VERSION "BYD Tang DM 2018 - sunnypilot 0.10.1"

NS_ :

BS_:

BU_: VCU EPS ESP MPC BCM RADAR

CM_ "BYD Tang DM 2018 CAN Database for sunnypilot";
CM_ "Version: 2026.02";
CM_ "Optimized for 18款比亚迪唐DM";

BO_ 85 EPB: 8 ESP
 SG_ EPB_ActiveFlag : 40|1@1+ (1,0) [0|1] "" VCU
 SG_ CheckSum : 56|8@1+ (1,0) [0|255] "" VCU

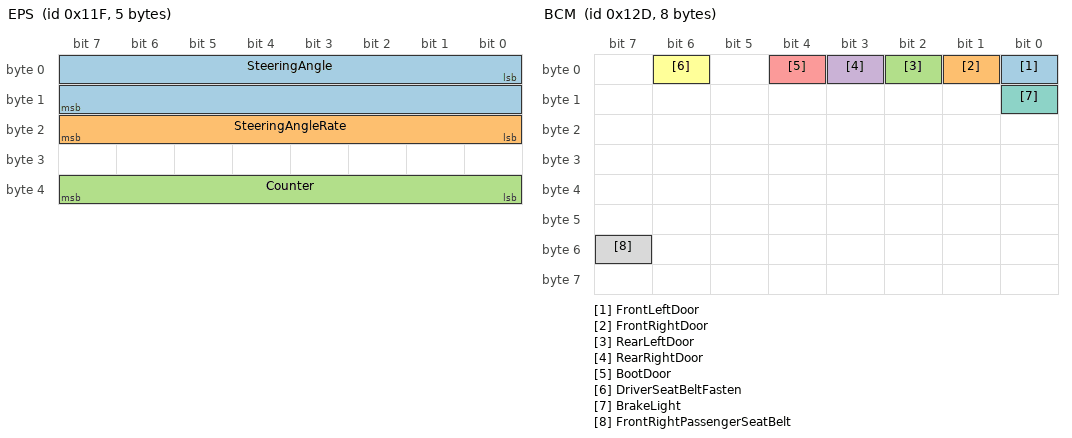
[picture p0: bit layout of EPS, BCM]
BO_ 287 EPS: 5 EPS
 SG_ SteeringAngle : 0|16@1- (0.1,0) [-450|450] "deg" VCU,MPC
 SG_ SteeringAngleRate : 16|8@1+ (4,0) [0|1020] "deg/s" VCU,MPC
 SG_ Counter : 32|8@1+ (1,0) [0|255] "" VCU

BO_ 289 CARSPEED: 8 VCU
 SG_ CarDisplaySpeed : 0|12@1+ (1,0) [0|255] "km/h" EPS,MPC

BO_ 301 BCM: 8 BCM
 SG_ FrontLeftDoor : 0|1@0+ (1,0) [0|1] "" VCU
 SG_ FrontRightDoor : 1|1@0+ (1,0) [0|1] "" VCU
 SG_ RearLeftDoor : 2|1@0+ (1,0) [0|1] "" VCU
 SG_ RearRightDoor : 3|1@0+ (1,0) [0|1] "" VCU
 SG_ BootDoor : 4|1@0+ (1,0) [0|1] "" VCU
 SG_ DriverSeatBeltFasten : 6|1@0+ (1,0) [0|1] "" VCU
 SG_ BrakeLight : 8|1@0+ (1,0) [0|1] "" VCU
 SG_ FrontRightPassengerSeatBelt : 55|1@0+ (1,0) [0|1] "" VCU

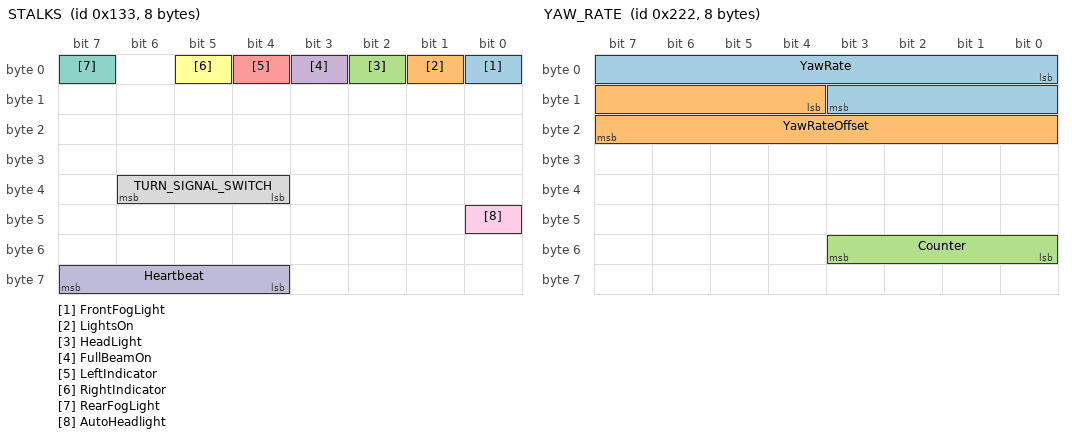
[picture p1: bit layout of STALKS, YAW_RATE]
BO_ 307 STALKS: 8 BCM
 SG_ FrontFogLight : 0|1@0+ (1,0) [0|1] "" VCU
 SG_ LightsOn : 1|1@1+ (1,0) [0|1] "" VCU
 SG_ HeadLight : 2|1@1+ (1,0) [0|1] "" VCU
 SG_ FullBeamOn : 3|1@1+ (1,0) [0|1] "" VCU
 SG_ LeftIndicator : 4|1@0+ (1,0) [0|1] "" VCU,MPC
 SG_ RightIndicator : 5|1@0+ (1,0) [0|1] "" VCU,MPC
 SG_ RearFogLight : 7|1@0+ (1,0) [0|1] "" VCU
 SG_ TURN_SIGNAL_SWITCH : 36|3@1+ (1,0) [0|7] "" VCU
 SG_ AutoHeadlight : 40|1@0+ (1,0) [0|1] "" VCU
 SG_ Heartbeat : 63|4@0+ (1,0) [0|15] "" VCU

BO_ 546 YAW_RATE: 8 ESP
 SG_ YawRate : 0|12@1+ (0.002133,-2.094) [-2.0|2.0] "rad/s" VCU,MPC
 SG_ YawRateOffset : 12|12@1+ (0.002133,-0.13) [-0.1|0.1] "rad/s" VCU
 SG_ Counter : 48|4@1+ (1,0) [0|15] "" VCU

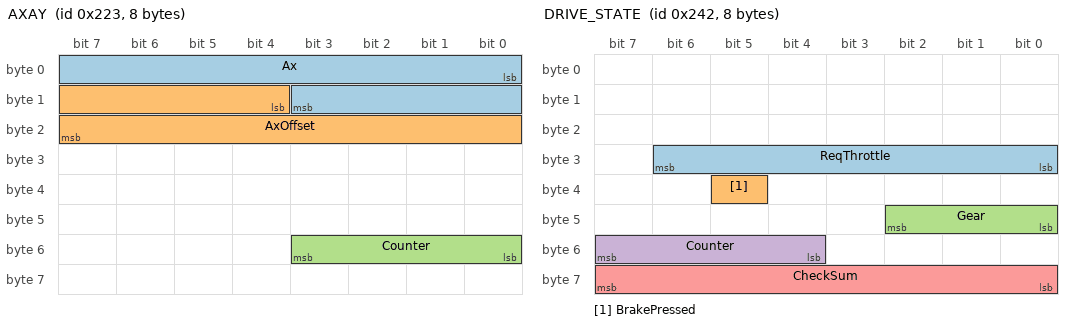
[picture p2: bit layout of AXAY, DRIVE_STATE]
BO_ 547 AXAY: 8 ESP
 SG_ Ax : 0|12@1+ (0.027167,-21.593) [-10.0|10.0] "m/s^2" VCU,MPC
 SG_ AxOffset : 12|12@1+ (0.027127,-21.593) [-1.0|1.0] "m/s^2" VCU
 SG_ Counter : 48|4@1+ (1,0) [0|15] "" VCU

BO_ 578 DRIVE_STATE: 8 VCU
 SG_ ReqThrottle : 30|7@0+ (1,0) [0|127] "%" EPS
 SG_ BrakePressed : 37|1@0+ (1,0) [0|1] "" EPS,MPC
 SG_ Gear : 40|3@1+ (1,0) [0|7] "" EPS,MPC
 SG_ Counter : 55|4@0+ (1,0) [0|15] "" EPS
 SG_ CheckSum : 56|8@1+ (1,0) [0|255] "" EPS

BO_ 660 BELT: 8 BCM
 SG_ SeatBeat : 16|2@1+ (1,0) [0|3] "" VCU

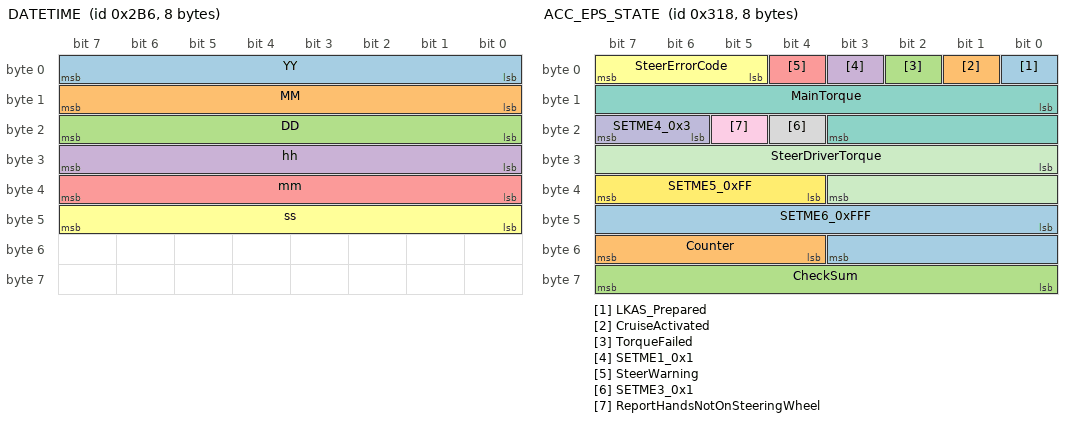
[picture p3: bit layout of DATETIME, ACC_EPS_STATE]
BO_ 694 DATETIME: 8 BCM
 SG_ YY : 7|8@0+ (1,0) [0|255] "" VCU
 SG_ MM : 15|8@0+ (1,0) [0|255] "" VCU
 SG_ DD : 23|8@0+ (1,0) [0|255] "" VCU
 SG_ hh : 31|8@0+ (1,0) [0|255] "" VCU
 SG_ mm : 39|8@0+ (1,0) [0|255] "" VCU
 SG_ ss : 47|8@0+ (1,0) [0|255] "" VCU

BO_ 790 ACC_MPC_STATE: 8 MPC
 SG_ AutoFullBeamState : 3|4@0+ (1,0) [0|15] "" VCU
 SG_ LeftLaneState : 4|2@1+ (1,0) [0|3] "" VCU
 SG_ LKAS_Config : 6|2@1+ (1,0) [0|3] "" VCU
 SG_ SETME2_0x1 : 8|2@1+ (1,0) [0|3] "" VCU
 SG_ ReqHandsOnSteeringWheel : 10|1@1+ (1,0) [0|1] "" VCU
 SG_ MPC_State : 11|4@1+ (1,0) [0|15] "" VCU
 SG_ AutoFullBeam_OnOff : 15|1@0+ (1,0) [0|1] "" VCU
 SG_ LKAS_Output : 16|11@1- (1,0) [-1024|1023] "" EPS
 SG_ LKAS_ReqPrepare : 27|1@1+ (1,0) [0|1] "" EPS
 SG_ LKAS_Active : 28|1@1+ (1,0) [0|1] "" EPS,VCU
 SG_ SETME3_0x0 : 29|1@0+ (1,0) [0|1] "" VCU
 SG_ TrafficSignRecognition_OnOff : 30|1@0+ (1,0) [0|1] "" VCU
 SG_ SETME4_0x0 : 31|1@0+ (1,0) [0|1] "" VCU
 SG_ SETME5_0x1 : 32|2@1+ (1,0) [0|3] "" VCU
 SG_ RightLaneState : 34|2@1+ (1,0) [0|3] "" VCU
 SG_ LKAS_State : 36|4@1+ (1,0) [0|15] "" VCU
 SG_ TrafficSignRecognition_Result : 40|8@1+ (5,-5) [-5|1270] "km/h" VCU
 SG_ LKAS_AlarmType : 49|2@0+ (1,0) [0|3] "" VCU
 SG_ SETME7_0x3 : 51|2@0+ (1,0) [0|3] "" VCU
 SG_ Counter : 52|4@1+ (1,0) [0|15] "" VCU
 SG_ CheckSum : 56|8@1+ (1,0) [0|255] "" VCU

BO_ 792 ACC_EPS_STATE: 8 EPS
 SG_ LKAS_Prepared : 0|1@1+ (1,0) [0|1] "" MPC
 SG_ CruiseActivated : 1|1@1+ (1,0) [0|1] "" MPC
 SG_ TorqueFailed : 2|1@1+ (1,0) [0|1] "" MPC
 SG_ SETME1_0x1 : 3|1@1+ (1,0) [0|1] "" MPC
 SG_ SteerWarning : 4|1@1+ (1,0) [0|1] "" MPC,VCU
 SG_ SteerErrorCode : 5|3@1+ (1,0) [0|7] "" MPC,VCU
 SG_ MainTorque : 8|12@1- (1,0) [-2048|2047] "" MPC
 SG_ SETME3_0x1 : 20|1@1+ (1,0) [0|1] "" MPC
 SG_ ReportHandsNotOnSteeringWheel : 21|1@1+ (1,0) [0|1] "" MPC,VCU
 SG_ SETME4_0x3 : 22|2@1+ (1,0) [0|3] "" MPC
 SG_ SteerDriverTorque : 24|12@1- (1,0) [-2048|2047] "" MPC,VCU
 SG_ SETME5_0xFF : 36|4@1+ (1,0) [0|15] "" MPC
 SG_ SETME6_0xFFF : 40|12@1+ (1,0) [0|4095] "" MPC
 SG_ Counter : 52|4@1+ (1,0) [0|15] "" MPC
 SG_ CheckSum : 56|8@1+ (1,0) [0|255] "" MPC

BO_ 813 ACC_HUD_ADAS: 8 MPC
 SG_ SetSpeed : 0|9@1+ (0.5,0) [0|255.5] "km/h" VCU
 SG_ HasLead : 9|1@1+ (1,0) [0|1] "" VCU
 SG_ SetDistance : 10|3@1+ (1,0) [0|7] "" VCU
 SG_ LeadingDistance : 13|3@1+ (1,0) [0|7] "" VCU
 SG_ AEB : 16|1@1+ (1,0) [0|1] "" VCU,ESP
 SG_ FCW : 17|1@1+ (1,0) [0|1] "" VCU
 SG_ SETME1_0x1 : 18|1@1+ (1,0) [0|1] "" VCU
 SG_ AccState : 19|3@1+ (1,0) [0|7] "" VCU
 SG_ AccOn1 : 22|1@0+ (1,0) [0|1] "" VCU
 SG_ CloseWarning : 23|1@0+ (1,0) [0|1] "" VCU
 SG_ SETME2_0x1 : 24|1@1+ (1,0) [0|1] "" VCU
 SG_ Notify : 25|7@1+ (1,0) [0|127] "" VCU
 SG_ Status : 32|4@1+ (1,0) [0|15] "" VCU
 SG_ SETME3_0xFFF : 36|12@1+ (1,0) [0|4095] "" VCU
 SG_ Counter : 48|4@1+ (1,0) [0|15] "" VCU
 SG_ SETME4_0xF : 55|4@0+ (1,0) [0|15] "" VCU
 SG_ CheckSum : 56|8@1+ (1,0) [0|255] "" VCU

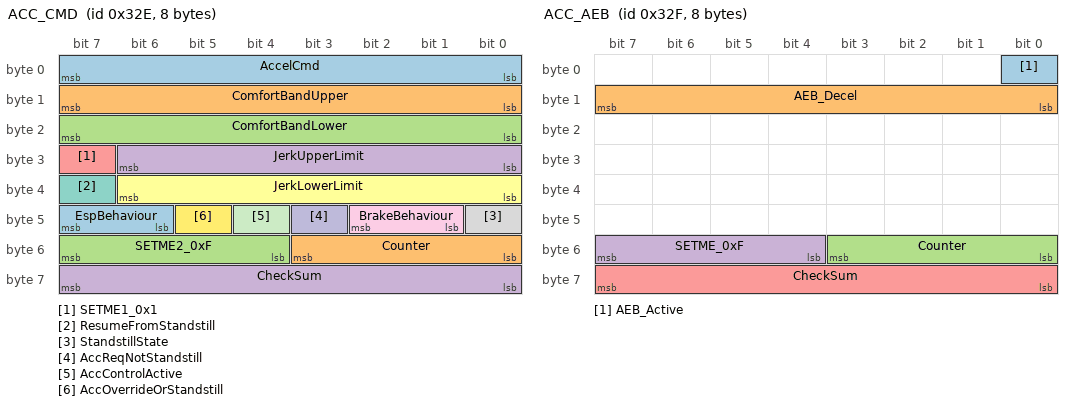
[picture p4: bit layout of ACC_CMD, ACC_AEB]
BO_ 814 ACC_CMD: 8 MPC
 SG_ AccelCmd : 0|8@1+ (0.05,-5) [-5|7.75] "m/s^2" ESP
 SG_ ComfortBandUpper : 8|8@1+ (0.05,-5) [-5|7.75] "m/s^2" ESP
 SG_ ComfortBandLower : 16|8@1+ (0.05,-5) [-5|7.75] "m/s^2" ESP
 SG_ JerkUpperLimit : 24|7@1+ (0.2,0) [0|12.7] "m/s^3" ESP
 SG_ SETME1_0x1 : 31|1@0+ (1,0) [0|1] "" ESP
 SG_ JerkLowerLimit : 32|7@1+ (0.2,-16) [-16|12.7] "m/s^3" ESP
 SG_ ResumeFromStandstill : 39|1@0+ (1,0) [0|1] "" ESP
 SG_ StandstillState : 40|1@0+ (1,0) [0|1] "" ESP
 SG_ BrakeBehaviour : 41|2@1+ (1,0) [0|3] "" ESP
 SG_ AccReqNotStandstill : 43|1@1+ (1,0) [0|1] "" ESP
 SG_ AccControlActive : 44|1@0+ (1,0) [0|1] "" ESP
 SG_ AccOverrideOrStandstill : 45|1@0+ (1,0) [0|1] "" ESP
 SG_ EspBehaviour : 46|2@1+ (1,0) [0|3] "" ESP
 SG_ Counter : 48|4@1+ (1,0) [0|15] "" ESP
 SG_ SETME2_0xF : 55|4@0+ (1,0) [0|15] "" ESP
 SG_ CheckSum : 56|8@1+ (1,0) [0|255] "" ESP

BO_ 815 ACC_AEB: 8 MPC
 SG_ AEB_Active : 0|1@1+ (1,0) [0|1] "" ESP
 SG_ AEB_Decel : 8|8@1+ (0.05,0) [0|12.75] "m/s^2" ESP
 SG_ Counter : 48|4@1+ (1,0) [0|15] "" ESP
 SG_ SETME_0xF : 55|4@0+ (1,0) [0|15] "" ESP
 SG_ CheckSum : 56|8@1+ (1,0) [0|255] "" ESP

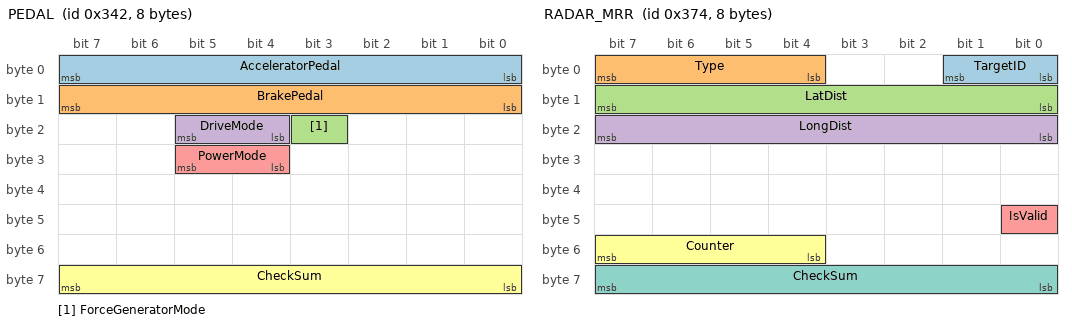
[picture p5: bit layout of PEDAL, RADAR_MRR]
BO_ 834 PEDAL: 8 VCU
 SG_ AcceleratorPedal : 0|8@1+ (0.01,0) [0|2.55] "" MPC
 SG_ BrakePedal : 8|8@1+ (0.01,0) [0|2.55] "" MPC
 SG_ ForceGeneratorMode : 19|1@1+ (1,0) [0|1] "" MPC
 SG_ DriveMode : 20|2@1+ (1,0) [0|3] "" MPC
 SG_ PowerMode : 28|2@1+ (1,0) [0|3] "" MPC
 SG_ CheckSum : 56|8@1+ (1,0) [0|255] "" MPC

BO_ 884 RADAR_MRR: 8 RADAR
 SG_ TargetID : 1|2@0+ (1,0) [0|3] "" MPC
 SG_ Type : 7|4@0+ (1,0) [0|15] "" MPC
 SG_ LatDist : 15|8@0+ (0.1,-12) [-12|13.5] "m" MPC
 SG_ LongDist : 23|8@0+ (1,-100) [-100|155] "m" MPC
 SG_ IsValid : 40|1@0+ (1,0) [0|1] "" MPC
 SG_ Counter : 52|4@1+ (1,0) [0|15] "" MPC
 SG_ CheckSum : 56|8@1+ (1,0) [0|255] "" MPC

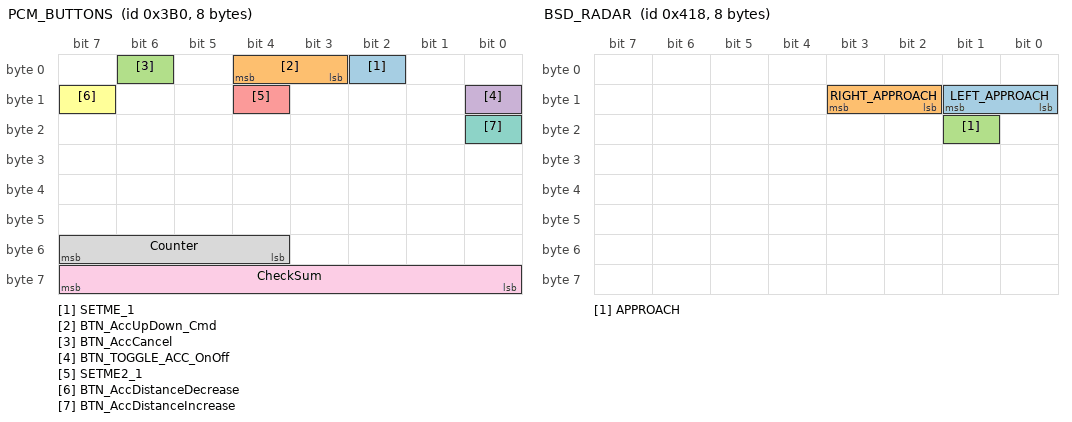
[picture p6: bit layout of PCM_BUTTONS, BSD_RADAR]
BO_ 944 PCM_BUTTONS: 8 BCM
 SG_ SETME_1 : 2|1@0+ (1,0) [0|1] "" VCU
 SG_ BTN_AccUpDown_Cmd : 4|2@0+ (1,0) [0|3] "" VCU,MPC
 SG_ BTN_AccCancel : 6|1@0+ (1,0) [0|1] "" VCU,MPC
 SG_ BTN_TOGGLE_ACC_OnOff : 8|1@0+ (1,0) [0|1] "" VCU,MPC
 SG_ SETME2_1 : 12|1@0+ (1,0) [0|1] "" VCU
 SG_ BTN_AccDistanceDecrease : 15|1@0+ (1,0) [0|1] "" VCU,MPC
 SG_ BTN_AccDistanceIncrease : 16|1@0+ (1,0) [0|1] "" VCU,MPC
 SG_ Counter : 52|4@1+ (1,0) [0|15] "" VCU
 SG_ CheckSum : 56|8@1+ (1,0) [0|255] "" VCU

BO_ 1048 BSD_RADAR: 8 RADAR
 SG_ LEFT_APPROACH : 9|2@0+ (1,0) [0|3] "" VCU
 SG_ RIGHT_APPROACH : 11|2@0+ (1,0) [0|3] "" VCU
 SG_ APPROACH : 17|1@0+ (1,0) [0|1] "" VCU

CM_ SG_ 578 Gear "档位: 1=P, 2=R, 3=N, 4=D";
CM_ SG_ 790 LeftLaneState "车道线状态: 0=灰色, 1=绿色, 2=黄色, 3=红色";
CM_ SG_ 790 RightLaneState "车道线状态: 0=灰色, 1=绿色, 2=黄色, 3=红色";
CM_ SG_ 790 LKAS_Config "LKAS配置: 0=禁用, 1=报警, 2=LKA, 3=报警+LKA";
CM_ SG_ 790 LKAS_AlarmType "报警类型: 0=振动, 1=声音, 2=声音+振动";
CM_ SG_ 813 AccState "ACC状态: 0=关闭, 2=ACC开启, 3=ACC激活, 5=强制加速, 7=错误";
CM_ SG_ 813 SetDistance "跟车距离: 1-4档";
CM_ SG_ 834 DriveMode "驾驶模式: 0=雪地, 1=ECO, 2=运动";
CM_ SG_ 834 PowerMode "动力模式: 1=EV, 2=强制EV, 3=HEV";
CM_ SG_ 944 BTN_AccUpDown_Cmd "巡航按钮: 0=未按, 1=SET减速, 3=RES加速";

VAL_ 578 Gear 1 "P" 2 "R" 3 "N" 4 "D" ;
VAL_ 790 AutoFullBeamState 2 "AutoFullBeamInactive" 11 "AutoFullBeamActive" ;
VAL_ 790 LeftLaneState 0 "GRAY" 1 "GREEN" 2 "YELLOW" 3 "RED" ;
VAL_ 790 RightLaneState 0 "GRAY" 1 "GREEN" 2 "YELLOW" 3 "RED" ;
VAL_ 790 LKAS_Config 0 "DISABLE" 1 "ALARM" 2 "LKA" 3 "ALARM_AND_LKA" ;
VAL_ 790 LKAS_AlarmType 0 "VIBRATION" 1 "AUDIO" 2 "AUDIO_AND_VIBRATION" ;
VAL_ 813 AccState 0 "OFF" 2 "ACC_ON" 3 "ACC_ACTIVE" 5 "FORCE_ACCEL" 7 "ERROR" ;
VAL_ 813 SetDistance 1 "1BAR" 2 "2BAR" 3 "3BAR" 4 "4BAR" ;
VAL_ 813 Notify 0 "NONE" 8 "DISENGAGE" 12 "ENGAGE" 16 "FORCE_ACCEL" 20 "ACC_ON" 22 "OVERRIDE" 32 "ACC_OFF" 36 "ACC_ERROR" 48 "CHECK_GEAR_D" ;
VAL_ 834 DriveMode 0 "SNOW" 1 "ECO" 2 "SPORT" ;
VAL_ 834 PowerMode 1 "EV" 2 "FORCE_EV" 3 "HEV" ;
VAL_ 944 BTN_AccUpDown_Cmd 0 "NOTPRESSED" 1 "DOWN_SETSPEED" 3 "UP_RESETSPEED" ;

BA_DEF_ BO_ "GenMsgCycleTime" INT 0 10000;
BA_DEF_DEF_ "GenMsgCycleTime" 0;

BA_ "GenMsgCycleTime" BO_ 85 100;
BA_ "GenMsgCycleTime" BO_ 287 50;
BA_ "GenMsgCycleTime" BO_ 289 50;
BA_ "GenMsgCycleTime" BO_ 301 100;
BA_ "GenMsgCycleTime" BO_ 307 100;
BA_ "GenMsgCycleTime" BO_ 546 50;
BA_ "GenMsgCycleTime" BO_ 547 50;
BA_ "GenMsgCycleTime" BO_ 578 50;
BA_ "GenMsgCycleTime" BO_ 660 100;
BA_ "GenMsgCycleTime" BO_ 694 1000;
BA_ "GenMsgCycleTime" BO_ 790 50;
BA_ "GenMsgCycleTime" BO_ 792 50;
BA_ "GenMsgCycleTime" BO_ 813 50;
BA_ "GenMsgCycleTime" BO_ 814 50;
BA_ "GenMsgCycleTime" BO_ 815 50;
BA_ "GenMsgCycleTime" BO_ 834 50;
BA_ "GenMsgCycleTime" BO_ 884 50;
BA_ "GenMsgCycleTime" BO_ 944 50;
BA_ "GenMsgCycleTime" BO_ 1048 100;
